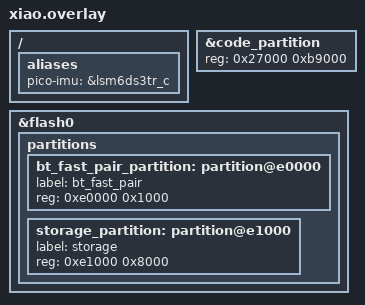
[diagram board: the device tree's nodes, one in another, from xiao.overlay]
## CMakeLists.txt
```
cmake_minimum_required(VERSION 3.20.0)
if(NOT PICO_NRF_DIR OR NOT EXISTS "${PICO_NRF_DIR}/samples/bluetooth/fast_pair/locator_tag/src/main.c")
  message(FATAL_ERROR "Set PICO_NRF_DIR to the nRF Connect SDK 3.4.2 nrf directory; use build.py")
endif()
set(FHN_SAMPLE "${PICO_NRF_DIR}/samples/bluetooth/fast_pair/locator_tag")
set(ENV{PICO_FHN_SAMPLE_DIR} "${FHN_SAMPLE}")
set(CONF_FILE "${FHN_SAMPLE}/configuration/prj.conf;${CMAKE_CURRENT_SOURCE_DIR}/prj.conf")
set(DTC_OVERLAY_FILE "${CMAKE_CURRENT_SOURCE_DIR}/xiao.overlay")
if(PICO_FHN_AUDIO)
  list(APPEND CONF_FILE "${CMAKE_CURRENT_SOURCE_DIR}/audio.conf")
  list(APPEND DTC_OVERLAY_FILE "${CMAKE_CURRENT_SOURCE_DIR}/../../overlays/xiao_ble_audio.overlay")
endif()
find_package(Zephyr REQUIRED HINTS $ENV{ZEPHYR_BASE})
project(pico_find_hub_probe LANGUAGES C CXX)
if(NOT CONFIG_BOARD_TARGET STREQUAL "xiao_ble/nrf52840/sense")
  message(FATAL_ERROR "This experiment is only mapped for xiao_ble/nrf52840/sense")
endif()
set(PICO_FW "${CMAKE_CURRENT_SOURCE_DIR}/../..")
target_include_directories(app PRIVATE "${FHN_SAMPLE}/include" "${FHN_SAMPLE}/src/ui"
  "${PICO_FW}/lib/pico_core/include" "${PICO_FW}/src")
# Reuse the version-pinned SDK protocol, state machine and DULT implementation;
# replace DK-only buttons, battery emulation and ADXL362 hardware adapters.
target_sources(app PRIVATE "${FHN_SAMPLE}/src/main.c" "${FHN_SAMPLE}/src/factory_reset.c"
  "${FHN_SAMPLE}/src/ring.c" "${FHN_SAMPLE}/src/ui/common.c" src/xiao.cpp
  "${PICO_FW}/src/platform/pico_display.cpp" "${PICO_FW}/src/platform/pico_audio.cpp"
  "${PICO_FW}/src/platform/pico_motion.cpp" "${PICO_FW}/src/platform/pico_status_led.cpp"
  "${PICO_FW}/lib/pico_core/src/display_model.cpp" "${PICO_FW}/lib/pico_core/src/clock.cpp"
  "${PICO_FW}/lib/pico_core/src/audio.cpp"
  "${PICO_FW}/lib/pico_core/src/pitch.cpp" "${PICO_FW}/lib/pico_core/src/motion.cpp")
zephyr_linker_sources(SECTIONS "${FHN_SAMPLE}/src/factory_reset_callbacks.ld")
zephyr_linker_sources(DATA_SECTIONS "${FHN_SAMPLE}/src/ui/request_listener.ld")
```

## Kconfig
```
# SDK app symbols and Zephyr configuration are defined by the pinned sample.
source "$(PICO_FHN_SAMPLE_DIR)/Kconfig"
menu "Pico isolated Find Hub prototype"
config PICO_LOG_LEVEL
    int
    default 3
config PICO_DISPLAY
    bool
    default y
    depends on DISPLAY
config PICO_MOTION
    bool
    default y
    depends on SENSOR && LSM6DSL
config PICO_AUDIO_I2S
    bool "Optional MAX98357 I2S speaker"
    depends on I2S
    default n
config PICO_AUDIO_VOLUME_PERCENT
    int
    default 25
endmenu
```

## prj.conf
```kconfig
# Preserve the XIAO UF2 bootloader; package only through the guarded helper.
CONFIG_USE_DT_CODE_PARTITION=y
CONFIG_BUILD_OUTPUT_UF2=n
CONFIG_BOOTLOADER_MCUBOOT=n
CONFIG_APP_DFU=n
CONFIG_DK_LIBRARY=n
CONFIG_BT_DEVICE_NAME="Pico FHN prototype"
CONFIG_NCS_APPLICATION_BOOT_BANNER_STRING="Pico isolated Find Hub prototype"
CONFIG_BT_FAST_PAIR_FHN_DULT_MODEL_NAME="Pico FHN prototype"
CONFIG_BT_FAST_PAIR_FHN_DULT_MANUFACTURER_NAME="BNextDigital"
CONFIG_BT_FAST_PAIR_FHN_RING_COMP_ONE=y
# Battery is explicitly unavailable; do not advertise a fake 100% reading.
CONFIG_BT_FAST_PAIR_FHN_BATTERY_DULT=n
# No DK-specific TX correction is asserted as calibrated for the XIAO antenna.
CONFIG_CPP=y
CONFIG_STD_CPP17=y
CONFIG_CPP_EXCEPTIONS=n
CONFIG_GLIBCXX_LIBCPP=y
CONFIG_MAIN_STACK_SIZE=4096
CONFIG_GPIO=y
CONFIG_I2C=y
CONFIG_DISPLAY=y
CONFIG_SSD1306=y
CONFIG_SENSOR=y
CONFIG_REGULATOR=y
CONFIG_LSM6DSL=y
CONFIG_LSM6DSL_TRIGGER_NONE=y
CONFIG_LSM6DSL_ACCEL_FS=4
CONFIG_LSM6DSL_ACCEL_ODR=0
CONFIG_LSM6DSL_GYRO_ODR=0
CONFIG_LOG_MODE_DEFERRED=y
CONFIG_LOG_BACKEND_UART=y
CONFIG_UART_CONSOLE=y
CONFIG_BOOT_DELAY=1000
CONFIG_BT_FAST_PAIR_FHN_DULT_FIRMWARE_VERSION_MAJOR=0
CONFIG_BT_FAST_PAIR_FHN_DULT_FIRMWARE_VERSION_MINOR=1
CONFIG_BT_FAST_PAIR_FHN_DULT_FIRMWARE_VERSION_REVISION=0
```

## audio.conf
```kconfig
CONFIG_I2S=y
CONFIG_PICO_AUDIO_I2S=y
```

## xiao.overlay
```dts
/* Prototype only. Never use the DK partition layout on this board. */
#include "../../overlays/xiao_ble_ssd1306.overlay"
/ {
    aliases { pico-imu = &lsm6ds3tr_c; };
};
&code_partition { reg = <0x27000 0xb9000>; };
&flash0 {
    partitions {
        /* Leave the normal Pico 0xec000..0xf4000 settings area untouched. */
        /delete-node/ partition@ec000;
        bt_fast_pair_partition: partition@e0000 {
            label = "bt_fast_pair";
            reg = <0xe0000 0x1000>;
        };
        storage_partition: partition@e1000 {
            label = "storage";
            reg = <0xe1000 0x8000>;
        };
    };
};
```

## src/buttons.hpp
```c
#pragma once
#include <cstdint>
namespace pico::fhn {
enum class Action { None, Pairing, StopRinging, Identify, Recovery, Motion, Reset };
// Debounced two-button prototype controls. Chords never emit individual actions.
class Buttons {
public:
    Action update(unsigned raw, std::uint32_t now, bool ringing) {
        raw &= 3U;
        if (raw!=raw_) { raw_=raw; changed_=now; }
        if (now-changed_>=30U && stable_!=raw_) {
            const auto before=stable_; stable_=raw_;
            if (stable_ && ringing) { consumed_=true; return Action::StopRinging; }
            if (stable_==3U && !chord_) { chord_=true; chord_start_=now; }
            for (unsigned i=0;i<2;++i) {
                const auto bit=1U<<i;
                if ((stable_&bit) && !(before&bit)) pressed_[i]=now;
                if (!(stable_&bit) && (before&bit) && !chord_ && !consumed_) {
                    const auto held=now-pressed_[i];
                    return i==0 ? held>=3000U ? Action::Motion : Action::Pairing :
                                  held>=3000U ? Action::Recovery : Action::Identify;
                }
            }
        }
        if (stable_==3U && chord_ && !consumed_ && now-chord_start_>=5000U) {
            consumed_=true; return Action::Reset;
        }
        if (!stable_ && !raw_) { consumed_=false; chord_=false; }
        return Action::None;
    }
    bool pending() const { return raw_!=stable_ || stable_!=0 || chord_ || consumed_; }
private:
    unsigned raw_{0},stable_{0};
    bool chord_{false},consumed_{false};
    std::uint32_t changed_{0},pressed_[2]{},chord_start_{0};
};
}
```

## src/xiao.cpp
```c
#include <cerrno>
#include <algorithm>
#include <zephyr/kernel.h>
#include <zephyr/drivers/gpio.h>
#include <zephyr/logging/log.h>
#include <zephyr/sys/atomic.h>
#include <bluetooth/fast_pair/fhn/fhn.h>
#include "app_ui.h"
#include "app_ui_priv.h"
#include "app_battery.h"
#include "app_motion_detector.h"
#include "platform/pico_display.hpp"
#include "platform/pico_audio.hpp"
#include "platform/pico_motion.hpp"
#include "platform/pico_status_led.hpp"
#include "buttons.hpp"
LOG_MODULE_REGISTER(pico_fhn_ui, CONFIG_PICO_LOG_LEVEL);
namespace {
const gpio_dt_spec action=GPIO_DT_SPEC_GET(DT_ALIAS(pico_focus_button),gpios);
const gpio_dt_spec navigate=GPIO_DT_SPEC_GET(DT_ALIAS(pico_nav_button),gpios);
const gpio_dt_spec green=GPIO_DT_SPEC_GET(DT_ALIAS(pico_status_led),gpios);
const gpio_dt_spec red=GPIO_DT_SPEC_GET(DT_ALIAS(pico_status_red),gpios);
const gpio_dt_spec blue=GPIO_DT_SPEC_GET(DT_ALIAS(pico_status_blue),gpios);
gpio_callback action_callback,navigate_callback;
pico::platform::Display display;
pico::platform::Audio audio;
pico::platform::Motion motion;
pico::platform::StatusLed heartbeat;
pico::fhn::Buttons buttons;
atomic_t states, detector_enabled, detected;
std::uint32_t last_ring;
bool previous_ring;
void service(k_work *);
K_WORK_DELAYABLE_DEFINE(service_work,service);
void wake() { k_work_reschedule(&service_work,K_NO_WAIT); }
void edge(const device *,gpio_callback *,gpio_port_pins_t) { wake(); }
void send(pico::fhn::Action action)
{
    using A=pico::fhn::Action;
    app_ui_request request;
    switch (action) {
    case A::Pairing: request=APP_UI_REQUEST_FP_ADV_PAIRING_MODE_CHANGE; break;
    case A::StopRinging: request=APP_UI_REQUEST_RINGING_STOP; break;
    case A::Identify: request=APP_UI_REQUEST_ID_MODE_ENTER; break;
    case A::Recovery: request=APP_UI_REQUEST_RECOVERY_MODE_ENTER; break;
    case A::Motion: request=APP_UI_REQUEST_MOTION_INDICATE; break;
    case A::Reset: request=APP_UI_REQUEST_FACTORY_RESET; break;
    default: return;
    }
    // Fast Pair callbacks require the cooperative system workqueue, never ISR context.
    app_ui_request_broadcast(request);
}
void service(k_work *)
{
    const auto now=k_uptime_get_32();
    const auto snapshot=atomic_get(&states);
    const bool ringing=(snapshot & BIT(APP_UI_STATE_RINGING))!=0;
    const int a=gpio_pin_get_dt(&action),n=gpio_pin_get_dt(&navigate);
    if (a>=0 && n>=0) send(buttons.update((a ? 1U : 0U)|(n ? 2U : 0U),now,ringing));
    pico::State face;
    face.finding=ringing;
    face.mood=(snapshot & BIT(APP_UI_STATE_PROVISIONED)) ? pico::Mood::Happy : pico::Mood::Neutral;
    display.render(face); // existing cache skips identical OLED transfers
    if (ringing && (!previous_ring || now-last_ring>=1000U)) {
        audio.play(pico::audio::Cue::TimerComplete,25); last_ring=now;
    }
    previous_ring=ringing;
    const auto config=atomic_get(&detector_enabled) ? pico::motion::kAll : 0U;
    motion.poll(static_cast<std::uint8_t>(config));
    std::uint32_t delay=motion.next_poll_ms(static_cast<std::uint8_t>(config),now);
    if (buttons.pending() || a<0 || n<0) delay=std::min(delay,std::uint32_t{20});
    if (ringing) delay=std::min(delay,std::uint32_t{1000}-(now-last_ring));
    if (delay!=UINT32_MAX) k_work_schedule(&service_work,K_MSEC(delay));
}
int configure(const gpio_dt_spec &pin,gpio_callback &cb)
{
    if (!gpio_is_ready_dt(&pin)) return -ENODEV;
    int err=gpio_pin_configure_dt(&pin,GPIO_INPUT);
    if (err) return err;
    gpio_init_callback(&cb,edge,BIT(pin.pin));
    err=gpio_add_callback(pin.port,&cb);
    if (err) return err;
    return gpio_pin_interrupt_configure_dt(&pin,GPIO_INT_EDGE_BOTH);
}
bool motion_event(const pico::Event &event)
{
    if (event.kind==pico::EventKind::MotionActive || event.kind==pico::EventKind::MotionPickup ||
        event.kind==pico::EventKind::MotionRock) atomic_set(&detected,1);
    return true;
}
void detector_start() { atomic_set(&detector_enabled,1); atomic_clear(&detected); wake(); }
bool detector_period() {
    // Never silently report "no motion" after a runtime sensor failure.
    const bool movement=atomic_set(&detected,0)!=0;
    return !motion.ready() || movement;
}
void detector_stop() { atomic_clear(&detector_enabled); atomic_clear(&detected); wake(); }
void test_request(app_ui_request request) {
    if (request==APP_UI_REQUEST_MOTION_INDICATE && atomic_get(&detector_enabled)) {
        atomic_set(&detected,1); LOG_INF("Physical bench button injected a motion indication");
    }
}
APP_UI_REQUEST_LISTENER_REGISTER(pico_bench_request,test_request);
const bt_fast_pair_fhn_motion_detector_cb motion_callbacks{detector_start,detector_period,detector_stop};
}
extern "C" int app_ui_init(void)
{
    // All state, credentials and settings belong to this standalone experiment.
    display.init();
    if (!audio.init()) LOG_WRN("No sound output: visual-only bench prototype, not a compliant locator tag");
    audio.set_muted(false); // Pico's ordinary mute must not silence DULT indications.
    for (const auto &led : {red,blue}) if (gpio_is_ready_dt(&led)) gpio_pin_configure_dt(&led,GPIO_OUTPUT_INACTIVE);
    heartbeat.init(green);
    int err=configure(action,action_callback);
    if (!err) err=configure(navigate,navigate_callback);
    if (!err) wake();
    return err;
}
extern "C" int app_ui_state_change_indicate(app_ui_state state,bool active)
{
    if (state>=APP_UI_STATE_COUNT) return -EINVAL;
    atomic_set_bit_to(&states,state,active);
    LOG_INF("FHN UI state %u = %u",static_cast<unsigned>(state),active ? 1U : 0U);
    wake(); return 0;
}
extern "C" int app_battery_init(void)
{
    LOG_WRN("Battery percentage unavailable in this prototype; no simulated charge reading");
    return bt_fast_pair_fhn_battery_level_set(BT_FAST_PAIR_FHN_BATTERY_LEVEL_NONE);
}
extern "C" int app_motion_detector_init(void)
{
    if (!motion.init(motion_event)) return -ENODEV;
    return bt_fast_pair_fhn_motion_detector_cb_register(&motion_callbacks);
}
```
